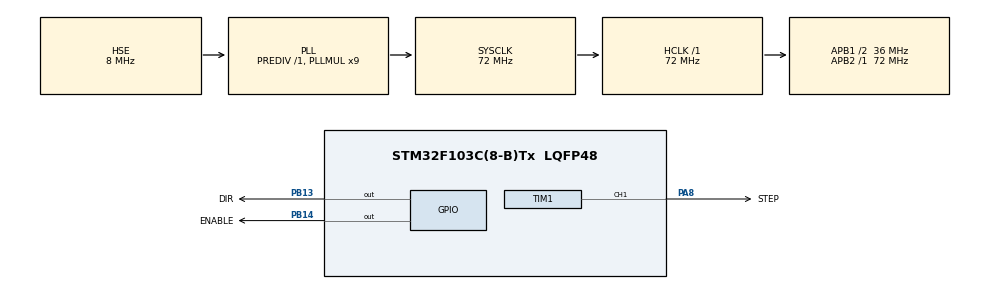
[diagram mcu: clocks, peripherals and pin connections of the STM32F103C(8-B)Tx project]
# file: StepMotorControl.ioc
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Mcu.Family=STM32F1
Mcu.Name=STM32F103C(8-B)Tx
Mcu.Package=LQFP48
NVIC.PriorityGroup=NVIC_PRIORITYGROUP_4
NVIC.TIM1_CC_IRQn=true\:0\:0\:false\:false\:true\:true\:true\:true
PA13.Mode=Serial_Wire
PA13.Signal=SYS_JTMS-SWDIO
PA14.Mode=Serial_Wire
PA14.Signal=SYS_JTCK-SWCLK
PA8.GPIO_Label=STEP
PA8.Signal=S_TIM1_CH1
PB13.GPIO_Label=DIR
PB13.GPIO_Speed=GPIO_SPEED_FREQ_HIGH
PB13.Signal=GPIO_Output
PB14.GPIO_Label=ENABLE
PB14.GPIO_Speed=GPIO_SPEED_FREQ_HIGH
PB14.PinState=GPIO_PIN_SET
PB14.Signal=GPIO_Output
PD0-OSC_IN.Mode=HSE-External-Oscillator
PD0-OSC_IN.Signal=RCC_OSC_IN
PD1-OSC_OUT.Mode=HSE-External-Oscillator
PD1-OSC_OUT.Signal=RCC_OSC_OUT
ProjectManager.HeapSize=0x200
ProjectManager.StackSize=0x400
ProjectManager.TargetToolchain=MDK-ARM V5.32
RCC.AHBFreq_Value=72000000
RCC.APB1CLKDivider=RCC_HCLK_DIV2
RCC.APB1Freq_Value=36000000
RCC.APB1TimFreq_Value=72000000
RCC.APB2Freq_Value=72000000
RCC.APB2TimFreq_Value=72000000
RCC.HCLKFreq_Value=72000000
RCC.PLLMUL=RCC_PLL_MUL9
RCC.PLLSourceVirtual=RCC_PLLSOURCE_HSE
RCC.SYSCLKFreq_VALUE=72000000
RCC.SYSCLKSource=RCC_SYSCLKSOURCE_PLLCLK
RCC.USBFreq_Value=72000000
SH.S_TIM1_CH1.0=TIM1_CH1,PWM Generation1 CH1
TIM1.Channel-PWM\ Generation1\ CH1=TIM_CHANNEL_1
TIM1.Period=1000-1
TIM1.Prescaler=72-1
TIM1.Pulse-PWM\ Generation1\ CH1=500
VP_TIM1_VS_ClockSourceINT.Mode=Internal
board=custom

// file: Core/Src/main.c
/* USER CODE BEGIN Header */
/**
 ******************************************************************************
 * @file           : main.c
 * @brief          : Main program body
 ******************************************************************************
 * @attention
 *
 * Copyright (c) 2026 STMicroelectronics.
 * All rights reserved.
 *
 * This software is licensed under terms that can be found in the LICENSE file
 * in the root directory of this software component.
 * If no LICENSE file comes with this software, it is provided AS-IS.
 *
 ******************************************************************************
 */
/* USER CODE END Header */
#include "main.h"

TIM_HandleTypeDef htim1;

void SystemClock_Config(void);
static void MX_GPIO_Init(void);
static void MX_TIM1_Init(void);

/* USER CODE BEGIN 0 */

StepMotor_t Motor1;

void HAL_TIM_PWM_PulseFinishedCallback(TIM_HandleTypeDef *htim)
{
  if (htim->Instance == Motor1.htim->Instance)
  {
    if (htim->Channel == Motor1.active_channel)
    {
      StepMotor_Update_IT(&Motor1);
    }
  }
}

/* USER CODE END 0 */

int main(void)
{

  /* MCU Configuration--------------------------------------------------------*/

  /* Reset of all peripherals, Initializes the Flash interface and the Systick. */
  HAL_Init();

  /* USER CODE BEGIN Init */
  OLED_Init();
  StepMotor_Init(&Motor1, &htim1, TIM_CHANNEL_1, GPIOB, GPIO_PIN_13, GPIOB, GPIO_PIN_14, 100.f);
  /* USER CODE END Init */

  /* Configure the system clock */
  SystemClock_Config();

  /* Initialize all configured peripherals */
  MX_GPIO_Init();
  MX_TIM1_Init();
  /* USER CODE BEGIN 2 */
  __HAL_TIM_SET_AUTORELOAD(&htim1, 2000 - 1);
  __HAL_TIM_SET_COMPARE(&htim1, TIM_CHANNEL_1, 1000);

  uint32_t total_steps = 800;
  uint32_t acc_steps = 0.2 * total_steps;
  uint32_t dec_steps = 0.2 * total_steps;

  char speed_info[16];
  char step_info[16];
  /* USER CODE END 2 */

  /* Infinite loop */
  /* USER CODE BEGIN WHILE */
  while (1)
  {
    // speed is from 30 to 6000
    StepMotor_Step_Trapezoid(&Motor1, 3000, total_steps, acc_steps, dec_steps, DIR1);
    while (Motor1.State != MOTOR_STOP)
    {
      snprintf(speed_info, sizeof(speed_info), "speed:%.2f     ", Motor1.Current_Speed);
      snprintf(step_info, sizeof(step_info), "step:%.2d      ", Motor1.Step_Now);

      OLED_ShowString(1, 1, speed_info);
      OLED_ShowString(2, 1, step_info);
    }
    snprintf(speed_info, sizeof(speed_info), "speed:%.2f     ", Motor1.Current_Speed);
    snprintf(step_info, sizeof(step_info), "step:%.2d      ", Motor1.Step_Now);
    OLED_ShowString(1, 1, speed_info);
    OLED_ShowString(2, 1, step_info);
    HAL_Delay(500);

    StepMotor_Step_Trapezoid(&Motor1, 6000, 2 * total_steps, 2 * acc_steps, 2 * dec_steps, DIR2);
    while (Motor1.State != MOTOR_STOP)
    {
      snprintf(speed_info, sizeof(speed_info), "speed:%.2f     ", Motor1.Current_Speed);
      snprintf(step_info, sizeof(step_info), "step:%.2d      ", Motor1.Step_Now);

      OLED_ShowString(1, 1, speed_info);
      OLED_ShowString(2, 1, step_info);
    }
    snprintf(speed_info, sizeof(speed_info), "speed:%.2f     ", Motor1.Current_Speed);
    snprintf(step_info, sizeof(step_info), "step:%.2d      ", Motor1.Step_Now);
    OLED_ShowString(1, 1, speed_info);
    OLED_ShowString(2, 1, step_info);
    HAL_Delay(500);

    /* USER CODE END WHILE */

  }
}

void SystemClock_Config(void)
{
  RCC_OscInitTypeDef RCC_OscInitStruct = {0};
  RCC_ClkInitTypeDef RCC_ClkInitStruct = {0};

  /** Initializes the RCC Oscillators according to the specified parameters
   * in the RCC_OscInitTypeDef structure.
   */
  RCC_OscInitStruct.OscillatorType = RCC_OSCILLATORTYPE_HSE;
  RCC_OscInitStruct.HSEState = RCC_HSE_ON;
  RCC_OscInitStruct.HSEPredivValue = RCC_HSE_PREDIV_DIV1;
  RCC_OscInitStruct.HSIState = RCC_HSI_ON;
  RCC_OscInitStruct.PLL.PLLState = RCC_PLL_ON;
  RCC_OscInitStruct.PLL.PLLSource = RCC_PLLSOURCE_HSE;
  RCC_OscInitStruct.PLL.PLLMUL = RCC_PLL_MUL9;
  if (HAL_RCC_OscConfig(&RCC_OscInitStruct) != HAL_OK)
  {
    Error_Handler();
  }

  /** Initializes the CPU, AHB and APB buses clocks
   */
  RCC_ClkInitStruct.ClockType = RCC_CLOCKTYPE_HCLK | RCC_CLOCKTYPE_SYSCLK | RCC_CLOCKTYPE_PCLK1 | RCC_CLOCKTYPE_PCLK2;
  RCC_ClkInitStruct.SYSCLKSource = RCC_SYSCLKSOURCE_PLLCLK;
  RCC_ClkInitStruct.AHBCLKDivider = RCC_SYSCLK_DIV1;
  RCC_ClkInitStruct.APB1CLKDivider = RCC_HCLK_DIV2;
  RCC_ClkInitStruct.APB2CLKDivider = RCC_HCLK_DIV1;

  if (HAL_RCC_ClockConfig(&RCC_ClkInitStruct, FLASH_LATENCY_2) != HAL_OK)
  {
    Error_Handler();
  }
}

static void MX_TIM1_Init(void)
{

  TIM_ClockConfigTypeDef sClockSourceConfig = {0};
  TIM_MasterConfigTypeDef sMasterConfig = {0};
  TIM_OC_InitTypeDef sConfigOC = {0};
  TIM_BreakDeadTimeConfigTypeDef sBreakDeadTimeConfig = {0};

  htim1.Instance = TIM1;
  htim1.Init.Prescaler = 72 - 1;
  htim1.Init.CounterMode = TIM_COUNTERMODE_UP;
  htim1.Init.Period = 1000 - 1;
  htim1.Init.ClockDivision = TIM_CLOCKDIVISION_DIV1;
  htim1.Init.RepetitionCounter = 0;
  htim1.Init.AutoReloadPreload = TIM_AUTORELOAD_PRELOAD_DISABLE;
  if (HAL_TIM_Base_Init(&htim1) != HAL_OK)
  {
    Error_Handler();
  }
  sClockSourceConfig.ClockSource = TIM_CLOCKSOURCE_INTERNAL;
  if (HAL_TIM_ConfigClockSource(&htim1, &sClockSourceConfig) != HAL_OK)
  {
    Error_Handler();
  }
  if (HAL_TIM_PWM_Init(&htim1) != HAL_OK)
  {
    Error_Handler();
  }
  sMasterConfig.MasterOutputTrigger = TIM_TRGO_RESET;
  sMasterConfig.MasterSlaveMode = TIM_MASTERSLAVEMODE_DISABLE;
  if (HAL_TIMEx_MasterConfigSynchronization(&htim1, &sMasterConfig) != HAL_OK)
  {
    Error_Handler();
  }
  sConfigOC.OCMode = TIM_OCMODE_PWM1;
  sConfigOC.Pulse = 500;
  sConfigOC.OCPolarity = TIM_OCPOLARITY_HIGH;
  sConfigOC.OCNPolarity = TIM_OCNPOLARITY_HIGH;
  sConfigOC.OCFastMode = TIM_OCFAST_DISABLE;
  sConfigOC.OCIdleState = TIM_OCIDLESTATE_RESET;
  sConfigOC.OCNIdleState = TIM_OCNIDLESTATE_RESET;
  if (HAL_TIM_PWM_ConfigChannel(&htim1, &sConfigOC, TIM_CHANNEL_1) != HAL_OK)
  {
    Error_Handler();
  }
  sBreakDeadTimeConfig.OffStateRunMode = TIM_OSSR_DISABLE;
  sBreakDeadTimeConfig.OffStateIDLEMode = TIM_OSSI_DISABLE;
  sBreakDeadTimeConfig.LockLevel = TIM_LOCKLEVEL_OFF;
  sBreakDeadTimeConfig.DeadTime = 0;
  sBreakDeadTimeConfig.BreakState = TIM_BREAK_DISABLE;
  sBreakDeadTimeConfig.BreakPolarity = TIM_BREAKPOLARITY_HIGH;
  sBreakDeadTimeConfig.AutomaticOutput = TIM_AUTOMATICOUTPUT_DISABLE;
  if (HAL_TIMEx_ConfigBreakDeadTime(&htim1, &sBreakDeadTimeConfig) != HAL_OK)
  {
    Error_Handler();
  }
  HAL_TIM_MspPostInit(&htim1);
}

static void MX_GPIO_Init(void)
{
  GPIO_InitTypeDef GPIO_InitStruct = {0};

  /* GPIO Ports Clock Enable */
  __HAL_RCC_GPIOD_CLK_ENABLE();
  __HAL_RCC_GPIOB_CLK_ENABLE();
  __HAL_RCC_GPIOA_CLK_ENABLE();

  /*Configure GPIO pin Output Level */
  HAL_GPIO_WritePin(DIR_GPIO_Port, DIR_Pin, GPIO_PIN_RESET);

  /*Configure GPIO pin Output Level */
  HAL_GPIO_WritePin(ENABLE_GPIO_Port, ENABLE_Pin, GPIO_PIN_SET);

  /*Configure GPIO pins : DIR_Pin ENABLE_Pin */
  GPIO_InitStruct.Pin = DIR_Pin | ENABLE_Pin;
  GPIO_InitStruct.Mode = GPIO_MODE_OUTPUT_PP;
  GPIO_InitStruct.Pull = GPIO_NOPULL;
  GPIO_InitStruct.Speed = GPIO_SPEED_FREQ_HIGH;
  HAL_GPIO_Init(GPIOB, &GPIO_InitStruct);

}

void Error_Handler(void)
{
  __disable_irq();
  while (1)
  {
  }
}
